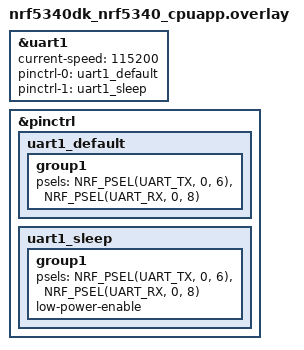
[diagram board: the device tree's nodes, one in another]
&uart1 {
    status = "okay";
    current-speed = <115200>;

    pinctrl-0 = <&uart1_default>;
    pinctrl-1 = <&uart1_sleep>;
    pinctrl-names = "default", "sleep";
};

&pinctrl {
    uart1_default: uart1_default {
        group1 {
            psels = <NRF_PSEL(UART_TX, 0, 6)>,
                    <NRF_PSEL(UART_RX, 0, 8)>;
        };
    };

    uart1_sleep: uart1_sleep {
        group1 {
            psels = <NRF_PSEL(UART_TX, 0, 6)>,
                    <NRF_PSEL(UART_RX, 0, 8)>;
            low-power-enable;
        };
    };
};
